# HC32F334J8TI register map
File version: 1.0
CPU: CM4 r0p1, little endian, MPU, FPU, 4 interrupt priority bits
Registers are 32-bit, read-write, reset 0x0 unless marked. A register's access mark holds for its fields unless they carry their own. Offsets are from the block's base; [hi:lo] are bit positions; {n}, {i} and the like mark numbered series.

## MCANRAM
Base 0x40073800
0x00 CKCR
  [1:0] ECCMOD
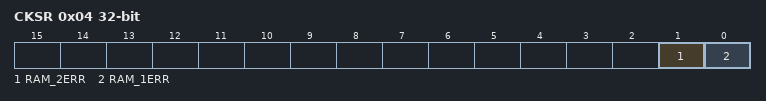
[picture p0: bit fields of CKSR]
0x04 CKSR
  [1] RAM_2ERR, [0] RAM_1ERR
0x08 EIEN
  [0] EIEN
0x0C EIBIT0
0x10 EIBIT1
  [6:0] EIBIT
0x14 ECCERRADDR ro
  [8:0] ECCERRADDR

## MPU
Base 0x40050000
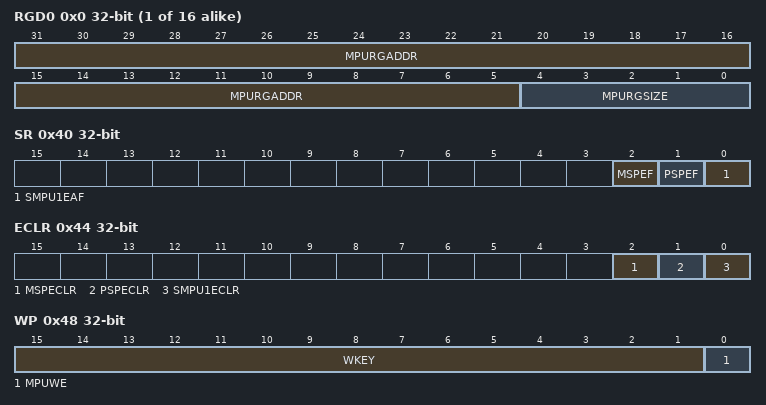
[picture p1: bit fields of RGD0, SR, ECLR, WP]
{0x0+4i} RGD{i} (i=0..15)
  [31:5] MPURGADDR, [4:0] MPURGSIZE
0x40 SR ro
  [2] MSPEF, [1] PSPEF, [0] SMPU1EAF
0x44 ECLR wo
  [2] MSPECLR, [1] PSPECLR, [0] SMPU1ECLR
0x48 WP
  [15:1] WKEY wo, [0] MPUWE
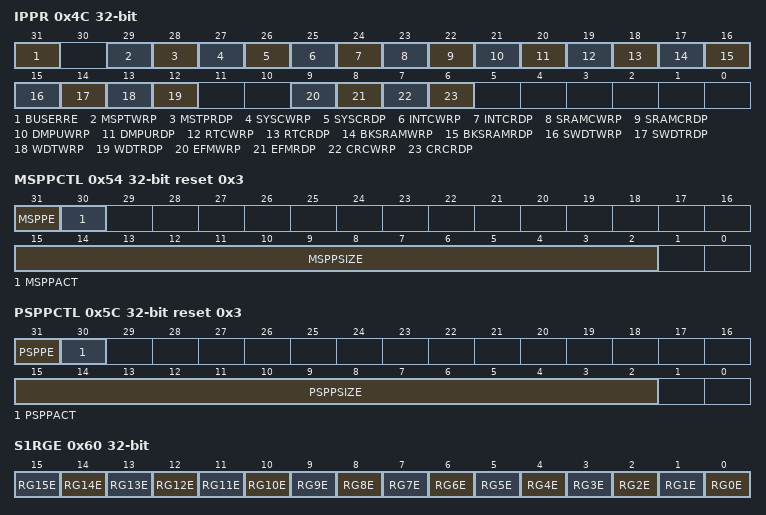
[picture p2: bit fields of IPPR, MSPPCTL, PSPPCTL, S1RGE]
0x4C IPPR
  [31] BUSERRE, [29] MSPTWRP, [28] MSTPRDP, [27] SYSCWRP, [26] SYSCRDP, [25] INTCWRP, [24] INTCRDP, [23] SRAMCWRP, [22] SRAMCRDP, [21] DMPUWRP, [20] DMPURDP, [19] RTCWRP, [18] RTCRDP, [17] BKSRAMWRP, [16] BKSRAMRDP, [15] SWDTWRP, [14] SWDTRDP, [13] WDTWRP, [12] WDTRDP, [9] EFMWRP, [8] EFMRDP, [7] CRCWRP, [6] CRCRDP
0x50 MSPPBA
  [31:2] MSPPBA
0x54 MSPPCTL reset 0x3
  [31] MSPPE, [30] MSPPACT, [15:2] MSPPSIZE
0x58 PSPPBA
  [31:2] PSPPBA
0x5C PSPPCTL reset 0x3
  [31] PSPPE, [30] PSPPACT, [15:2] PSPPSIZE
0x60 S1RGE
  [n] RG{n}E (n=0..15)
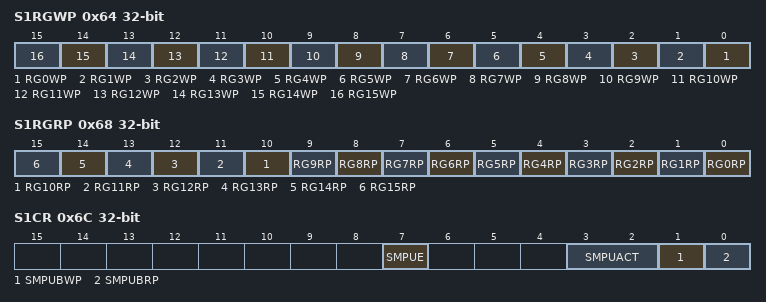
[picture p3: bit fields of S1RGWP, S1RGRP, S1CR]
0x64 S1RGWP
  [n] RG{n}WP (n=0..15)
0x68 S1RGRP
  [n] RG{n}RP (n=0..15)
0x6C S1CR
  [7] SMPUE, [3:2] SMPUACT, [1] SMPUBWP, [0] SMPUBRP

## PERIC
Base 0x40055400
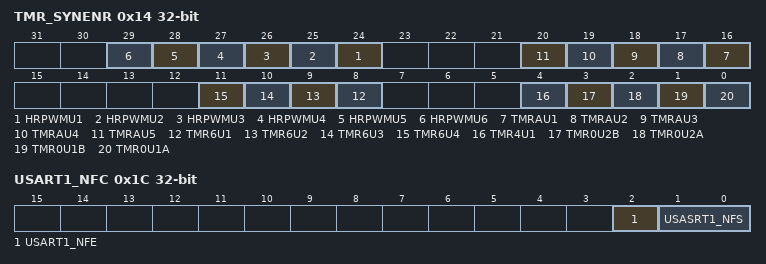
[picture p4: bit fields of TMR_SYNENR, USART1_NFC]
0x14 TMR_SYNENR
  [n+23] HRPWMU{n} (n=1..6), [n+15] TMRAU{n} (n=1..5), [n+7] TMR6U{n} (n=1..4), [4] TMR4U1, [3] TMR0U2B, [2] TMR0U2A, [1] TMR0U1B, [0] TMR0U1A
0x1C USART1_NFC
  [2] USART1_NFE, [1:0] USASRT1_NFS

## PLA
Base 0x4004FC00
0x00 GCTL
  [15:0] EN
0x0C STAT ro
  [15:0] OUT
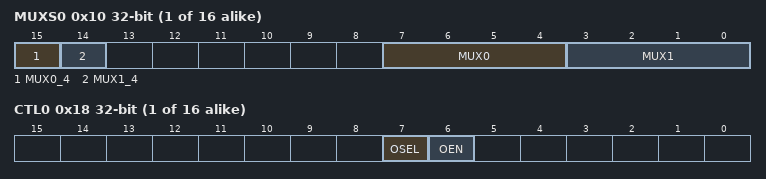
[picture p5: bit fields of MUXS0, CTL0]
{0x10+0xC*i} MUXS{i} (i=0..15)
  [15] MUX0_4, [14] MUX1_4, [7:4] MUX0, [3:0] MUX1
{0x14+0xC*i} LUTCTL{i} (i=0..15)
  [7:0] LUTCTL
{0x18+0xC*i} CTL{i} (i=0..15)
  [7] OSEL, [6] OEN

## PWC
Base 0x40048000; alternate view of CMU
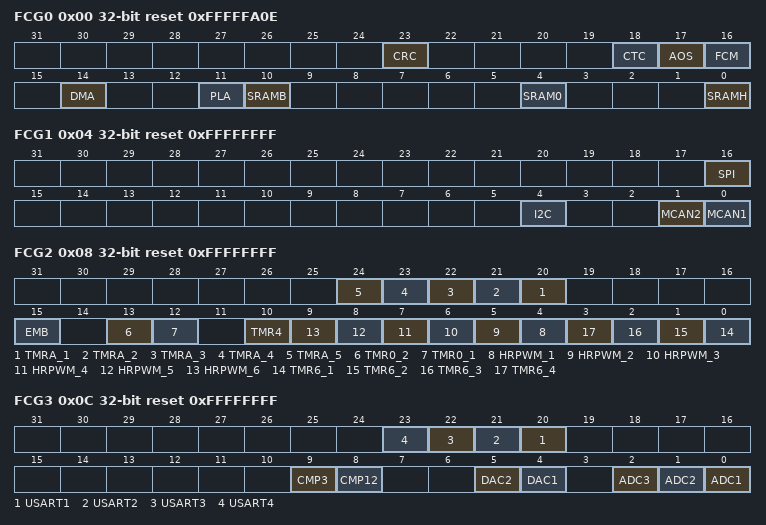
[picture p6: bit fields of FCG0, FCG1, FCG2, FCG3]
0x00 FCG0 reset 0xFFFFFA0E
  [23] CRC, [18] CTC, [17] AOS, [16] FCM, [14] DMA, [11] PLA, [10] SRAMB, [4] SRAM0, [0] SRAMH
0x04 FCG1 reset 0xFFFFFFFF
  [16] SPI, [4] I2C, [1] MCAN2, [0] MCAN1
0x08 FCG2 reset 0xFFFFFFFF
  [n+19] TMRA_{n} (n=1..5), [15] EMB, [13] TMR0_2, [12] TMR0_1, [10] TMR4, [n+3] HRPWM_{n} (n=1..6), [n-1] TMR6_{n} (n=1..4)
0x0C FCG3 reset 0xFFFFFFFF
  [n+19] USART{n} (n=1..4), [9] CMP3, [8] CMP12, [5] DAC2, [4] DAC1, [2] ADC3, [1] ADC2, [0] ADC1
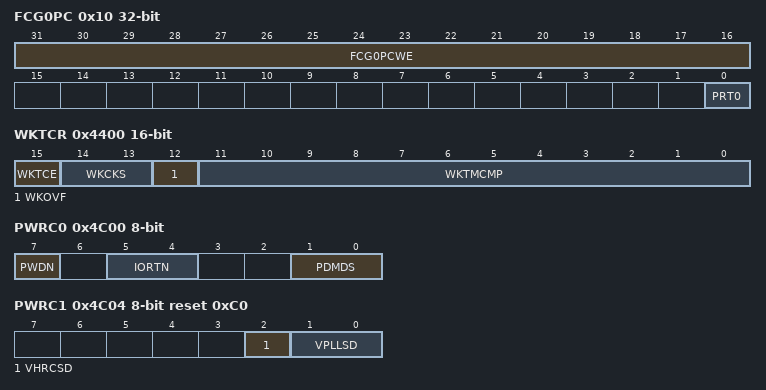
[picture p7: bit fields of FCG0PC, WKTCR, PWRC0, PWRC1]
0x10 FCG0PC
  [31:16] FCG0PCWE wo, [0] PRT0
0x4400 WKTCR 16-bit
  [15] WKTCE, [14:13] WKCKS, [12] WKOVF, [11:0] WKTMCMP
0x4C00 PWRC0 8-bit
  [7] PWDN, [5:4] IORTN, [1:0] PDMDS
0x4C04 PWRC1 8-bit reset 0xC0
  [2] VHRCSD, [1:0] VPLLSD
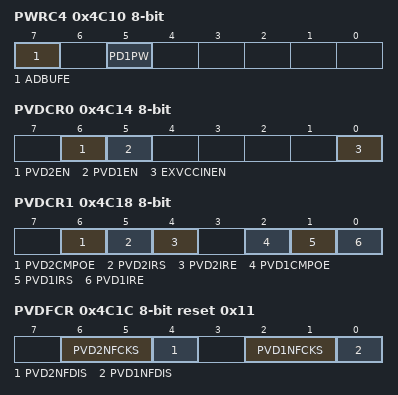
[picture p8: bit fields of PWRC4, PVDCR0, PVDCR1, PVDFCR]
0x4C10 PWRC4 8-bit
  [7] ADBUFE, [5] PD1PW
0x4C14 PVDCR0 8-bit
  [6] PVD2EN, [5] PVD1EN, [0] EXVCCINEN
0x4C18 PVDCR1 8-bit
  [6] PVD2CMPOE, [5] PVD2IRS, [4] PVD2IRE, [2] PVD1CMPOE, [1] PVD1IRS, [0] PVD1IRE
0x4C1C PVDFCR 8-bit reset 0x11
  [6:5] PVD2NFCKS, [4] PVD2NFDIS, [2:1] PVD1NFCKS, [0] PVD1NFDIS
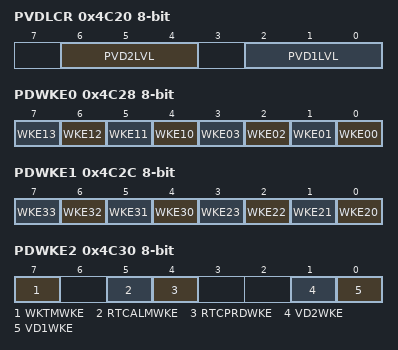
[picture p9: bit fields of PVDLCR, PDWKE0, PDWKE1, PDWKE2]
0x4C20 PVDLCR 8-bit
  [6:4] PVD2LVL, [2:0] PVD1LVL
0x4C28 PDWKE0 8-bit
  [n-6] WKE{n} (n=10..13), [n] WKE{n:02} (n=0..3)
0x4C2C PDWKE1 8-bit
  [n-26] WKE{n} (n=30..33), [n-20] WKE{n} (n=20..23)
0x4C30 PDWKE2 8-bit
  [7] WKTMWKE, [5] RTCALMWKE, [4] RTCPRDWKE, [1] VD2WKE, [0] VD1WKE
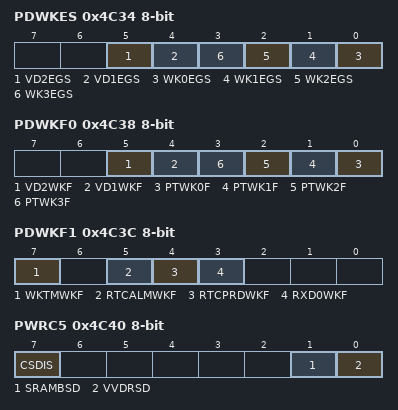
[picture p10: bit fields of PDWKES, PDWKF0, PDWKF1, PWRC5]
0x4C34 PDWKES 8-bit
  [5] VD2EGS, [4] VD1EGS, [n] WK{n}EGS (n=0..3)
0x4C38 PDWKF0 8-bit
  [5] VD2WKF, [4] VD1WKF, [n] PTWK{n}F (n=0..3)
0x4C3C PDWKF1 8-bit
  [7] WKTMWKF, [5] RTCALMWKF, [4] RTCPRDWKF, [3] RXD0WKF
0x4C40 PWRC5 8-bit
  [7] CSDIS, [1] SRAMBSD, [0] VVDRSD
0x4C44 PWRC6 8-bit
  [1:0] RTCCKSEL
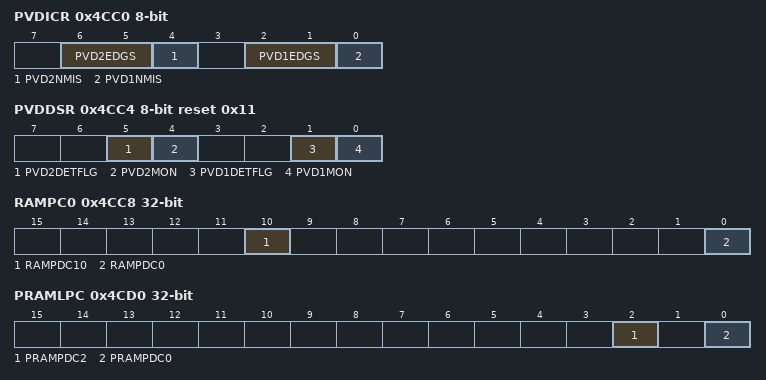
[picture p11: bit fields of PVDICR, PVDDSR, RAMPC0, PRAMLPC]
0x4CC0 PVDICR 8-bit
  [6:5] PVD2EDGS, [4] PVD2NMIS, [2:1] PVD1EDGS, [0] PVD1NMIS
0x4CC4 PVDDSR 8-bit reset 0x11
  [5] PVD2DETFLG, [4] PVD2MON, [1] PVD1DETFLG, [0] PVD1MON
0x4CC8 RAMPC0
  [10] RAMPDC10, [0] RAMPDC0
0x4CD0 PRAMLPC
  [2] PRAMPDC2, [0] PRAMPDC0
0x4CD8 LPMCSR 16-bit ro
  [0] LPMF
0x4CDA LPMCSCR 16-bit
  [0] LPMFC
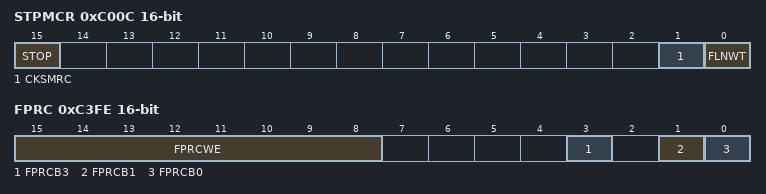
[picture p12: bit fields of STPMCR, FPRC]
0xC00C STPMCR 16-bit
  [15] STOP, [1] CKSMRC, [0] FLNWT
0xC3FE FPRC 16-bit
  [15:8] FPRCWE, [3] FPRCB3, [1] FPRCB1, [0] FPRCB0
